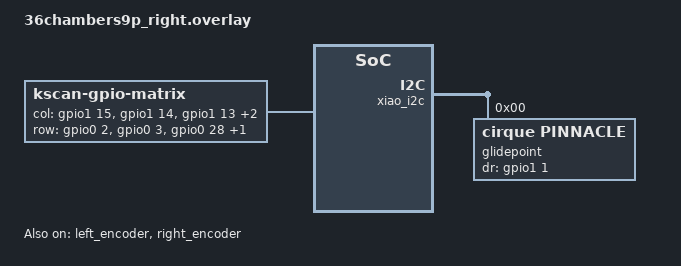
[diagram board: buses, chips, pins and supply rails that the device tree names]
#include "36chambers9p.dtsi" 
#include <dt-bindings/zmk/input_transform.h>
#include <input/processors.dtsi>
/*
CS(SS) pin is D16 P0.31
Encoder A and B for Right1 are D14 and D15, P0.09 and P0.10
Encoder A and B for Right2 are D11 and D12, P0.15 and P0.19
DR is D13, P1.01
SDA D4
SCL D5
MISO D18 P1.05
MOSI D19 P1.07
SCK  D17 P1.03 
*/
&default_transform {
	col-offset = <6>;
}; 


&left_encoder {
    status = "okay";
};
&right_encoder {
    status = "okay";
};

// Cirque I2C
&xiao_i2c {
    status = "okay";
    glidepoint: glidepoint@0 {
        compatible = "cirque,pinnacle";
        reg = <0>;
        status = "okay";
        dr-gpios = <&gpio1 1 (GPIO_ACTIVE_HIGH)>;
        // sensitivity = "4x";
        // sleep;
        no-taps;
    };
        // Rotation config, from Pete
    // This will change in the future
    // https://discord.com/channels/719497620560543766/845285481888743434/1206407883777114182
    // input_config {
    //     compatible = "zmk,input-configs";
    
    //     cirque_config {
    //         device = <&glidepoint>;
    //         xy-swap;
    //         y-invert;
    //         x-invert;
    //     };
    // };
};

// Cirque SPI
// // pin control for Xiao Plus
// &pinctrl {
//     /* configuration for spi0 device, default state */
//     spi0_default: spi0_default {
//         /* node name is arbitrary */
//         group1 {
//             /* main role: configure P0.01 as SPI clock, P0.02 as SPI MOSI, P0.03 as SPI MISO */
//             psels = <NRF_PSEL(SPIM_SCK,  1, 3)>,
//                     <NRF_PSEL(SPIM_MOSI, 1, 7)>,
//                     <NRF_PSEL(SPIM_MISO, 1, 5)>;
//         };
//     };
//     /* configuration for spi0 device, sleep state */
//     spi0_sleep: spi0_sleep {
//         group1 {
//             /* main role: configure P0.01 as SPI clock, P0.02 as SPI MOSI, P0.03 as SPI MISO */
//             psels = <NRF_PSEL(SPIM_SCK,  1, 3)>,
//                     <NRF_PSEL(SPIM_MOSI, 1, 7)>,
//                     <NRF_PSEL(SPIM_MISO, 1, 5)>;
//             low-power-enable;
//         };
//     };
// };

// &spi0 {
//     compatible = "nordic,nrf-spim";
//     pinctrl-0 = <&spi0_default>;
//     pinctrl-1 = <&spi0_sleep>;
//     pinctrl-names = "default", "sleep";
// };
// &spi0 {
//     status = "okay";
//     cs-gpios = <&gpio0 31 GPIO_ACTIVE_LOW>; 
//     glidepoint: glidepoint@0 {
//         compatible = "cirque,pinnacle";
//         reg = <0>;
//         spi-max-frequency = <1000000>;
//         status = "okay";
//         dr-gpios = <&gpio1 1 (GPIO_ACTIVE_HIGH)>; 
//         sensitivity = "4x";
//         // sleep;
//         // no-taps;
//     };
// };
/{
    glidepoint_listener {
        compatible = "zmk,input-listener";
        device = <&glidepoint>;
        // input-processors = <&zip_xy_transform (INPUT_TRANSFORM_XY_SWAP)>;
        input-processors = <
            &zip_xy_transform (INPUT_TRANSFORM_X_INVERT)
            &zip_xy_scaler 4 1
        >; // swap x and y, invert x and y
        // input-processors = <&zip_xy_scaler 5 2>; //2.5 faster cursor
        // input-processors = <&zip_xy_scaler 3 1>; // 3x faster cursor
        // input-processors = <&zip_xy_scaler 4 1>; // 4x faster cursor
    };
};

/{
    kscan0: kscan {
        compatible = "zmk,kscan-gpio-matrix";
        label = "KSCAN";
        diode-direction = "col2row";
        // compatible = "zmk,kscan-gpio-matrix";
        // diode-direction = "col2row";
    col-gpios
    	= <&gpio1 15 GPIO_ACTIVE_HIGH>//Col0
        , <&gpio1 14 GPIO_ACTIVE_HIGH>//Col1
        , <&gpio1 13 GPIO_ACTIVE_HIGH>//Col2
        , <&gpio1 12 GPIO_ACTIVE_HIGH>//Col3
        , <&gpio1 11 GPIO_ACTIVE_HIGH>//Col4
        ;
	row-gpios
        = <&gpio0 2 (GPIO_ACTIVE_HIGH | GPIO_PULL_DOWN)>   //Row2
        , <&gpio0 3 (GPIO_ACTIVE_HIGH | GPIO_PULL_DOWN)>   //Row3
        , <&gpio0 28 (GPIO_ACTIVE_HIGH | GPIO_PULL_DOWN)>  //Row0
        , <&gpio0 29 (GPIO_ACTIVE_HIGH | GPIO_PULL_DOWN)>   //Row1
        ;
    };
};

